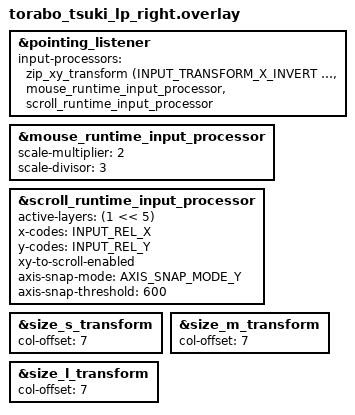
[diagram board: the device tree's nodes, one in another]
#include "torabo_tsuki_lp.dtsi"
#include <input/processors.dtsi>
#include <input/processors/runtime-input-processor.dtsi>
#include <dt-bindings/zmk/input_transform.h>
#include <dt-bindings/zmk/runtime_input_processor.h>
#include <zephyr/dt-bindings/input/input-event-codes.h>

&pointing_listener {
    input-processors = <&zip_xy_transform (INPUT_TRANSFORM_X_INVERT | INPUT_TRANSFORM_Y_INVERT)>,
                       <&mouse_runtime_input_processor>,
                       <&scroll_runtime_input_processor>;
};

/*
 * ここに書くのは「起動直後の初期値」。DYA Studio の Trackball タブから
 * 感度・回転・軸スナップ・有効レイヤー・自動レイヤー切替を実行時に変更でき、
 * 変更はフラッシュに保存される。
 */
&mouse_runtime_input_processor {
    /* 従来の <&zip_xy_scaler 2 3> と同じポインタ感度 */
    scale-multiplier = <2>;
    scale-divisor = <3>;
    /* 自動マウスレイヤーは既定では使わない (Studio から有効化できる) */
};

&scroll_runtime_input_processor {
    /* XY の動きをホイールに変換する。
       有効レイヤーは LT_SCR (keymap.keymap のスクロールレイヤー = 5) */
    active-layers = <(1 << 5)>;

    x-codes = <INPUT_REL_X>;
    y-codes = <INPUT_REL_Y>;
    xy-to-scroll-enabled;

    /* 縦スクロール優先。しきい値を超えたら横に切り替わる */
    axis-snap-mode = <AXIS_SNAP_MODE_Y>;
    axis-snap-threshold = <600>;
};

&size_s_transform {
    col-offset = <7>;
};

&size_m_transform {
    col-offset = <7>;
};

&size_l_transform {
    col-offset = <7>;
};
